AUTOSAR XML (schema 00046)
package /ComponentTypes
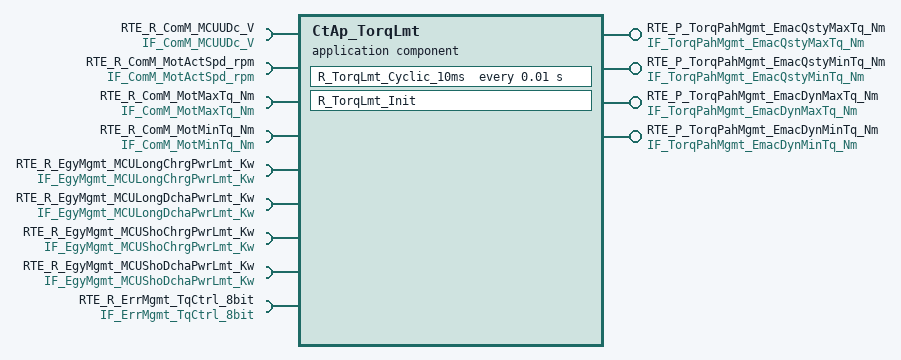
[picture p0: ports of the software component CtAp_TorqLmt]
  application sw component type CtAp_TorqLmt
    4 x provide port:
      RTE_P_TorqPahMgmt_EmacQstyMaxTq_Nm: nonqueued-sender-com-spec{data-element=tec_TorqPahMgmt_EmacQstyMaxTq_Nm, init-value=0}, provided-interface=IF_TorqPahMgmt_EmacQstyMaxTq_Nm
      RTE_P_TorqPahMgmt_EmacQstyMinTq_Nm: nonqueued-sender-com-spec{data-element=tec_TorqPahMgmt_EmacQstyMinTq_Nm, init-value=0}, provided-interface=IF_TorqPahMgmt_EmacQstyMinTq_Nm
      RTE_P_TorqPahMgmt_EmacDynMaxTq_Nm: nonqueued-sender-com-spec{data-element=tec_TorqPahMgmt_EmacDynMaxTq_Nm, init-value=0}, provided-interface=IF_TorqPahMgmt_EmacDynMaxTq_Nm
      RTE_P_TorqPahMgmt_EmacDynMinTq_Nm: nonqueued-sender-com-spec{data-element=tec_TorqPahMgmt_EmacDynMinTq_Nm, init-value=0}, provided-interface=IF_TorqPahMgmt_EmacDynMinTq_Nm
    9 x require port:
      RTE_R_ComM_MCUUDc_V: nonqueued-receiver-com-spec{data-element=tec_ComM_MCUUDc_V, filter=data-filter-type=ALWAYS, init-value=0}, required-interface=IF_ComM_MCUUDc_V
      RTE_R_ComM_MotActSpd_rpm: nonqueued-receiver-com-spec{data-element=tec_ComM_MotActSpd_rpm, filter=data-filter-type=ALWAYS, init-value=0}, required-interface=IF_ComM_MotActSpd_rpm
      RTE_R_ComM_MotMaxTq_Nm: nonqueued-receiver-com-spec{data-element=tec_ComM_MotMaxTq_Nm, filter=data-filter-type=ALWAYS, init-value=0}, required-interface=IF_ComM_MotMaxTq_Nm
      RTE_R_ComM_MotMinTq_Nm: nonqueued-receiver-com-spec{data-element=tec_ComM_MotMinTq_Nm, filter=data-filter-type=ALWAYS, init-value=0}, required-interface=IF_ComM_MotMinTq_Nm
      RTE_R_EgyMgmt_MCULongChrgPwrLmt_Kw: nonqueued-receiver-com-spec{data-element=tec_EgyMgmt_MCULongChrgPwrLmt_Kw, filter=data-filter-type=ALWAYS, init-value=0}, required-interface=IF_EgyMgmt_MCULongChrgPwrLmt_Kw
      RTE_R_EgyMgmt_MCULongDchaPwrLmt_Kw: nonqueued-receiver-com-spec{data-element=tec_EgyMgmt_MCULongDchaPwrLmt_Kw, filter=data-filter-type=ALWAYS, init-value=0}, required-interface=IF_EgyMgmt_MCULongDchaPwrLmt_Kw
      RTE_R_EgyMgmt_MCUShoChrgPwrLmt_Kw: nonqueued-receiver-com-spec{data-element=tec_EgyMgmt_MCUShoChrgPwrLmt_Kw, filter=data-filter-type=ALWAYS, init-value=0}, required-interface=IF_EgyMgmt_MCUShoChrgPwrLmt_Kw
      RTE_R_EgyMgmt_MCUShoDchaPwrLmt_Kw: nonqueued-receiver-com-spec{data-element=tec_EgyMgmt_MCUShoDchaPwrLmt_Kw, filter=data-filter-type=ALWAYS, init-value=0}, required-interface=IF_EgyMgmt_MCUShoDchaPwrLmt_Kw
      RTE_R_ErrMgmt_TqCtrl_8bit: nonqueued-receiver-com-spec{data-element=tec_ErrMgmt_TqCtrl_8bit, filter=data-filter-type=ALWAYS, init-value=0}, required-interface=IF_ErrMgmt_TqCtrl_8bit
    behavior CtAp_TorqLmt_InternalBehavior
      timing event TMT_R_TorqLmt_Cyclic_10ms: start-on-event=R_TorqLmt_Cyclic_10ms, period=0.01
      init event CtAp_TorqLmt_InitEvent: start-on-event=R_TorqLmt_Init
      runnable R_TorqLmt_Cyclic_10ms
        data-receive-point-by-arguments:
          9 x access:
            REC_RTE_R_ComM_MCUUDc_V_tec_ComM_MCUUDc_V: accessed-variable=RTE_R_ComM_MCUUDc_V.tec_ComM_MCUUDc_V
            REC_RTE_R_ComM_MotActSpd_rpm_tec_ComM_MotActSpd_rpm: accessed-variable=RTE_R_ComM_MotActSpd_rpm.tec_ComM_MotActSpd_rpm
            REC_RTE_R_ComM_MotMaxTq_Nm_tec_ComM_MotMaxTq_Nm: accessed-variable=RTE_R_ComM_MotMaxTq_Nm.tec_ComM_MotMaxTq_Nm
            REC_RTE_R_ComM_MotMinTq_Nm_tec_ComM_MotMinTq_Nm: accessed-variable=RTE_R_ComM_MotMinTq_Nm.tec_ComM_MotMinTq_Nm
            REC_RTE_R_EgyMgmt_MCULongChrgPwrLmt_Kw_tec_EgyMgmt_MCULongChrgPwrLmt_Kw: accessed-variable=RTE_R_EgyMgmt_MCULongChrgPwrLmt_Kw.tec_EgyMgmt_MCULongChrgPwrLmt_Kw
            REC_RTE_R_EgyMgmt_MCULongDchaPwrLmt_Kw_tec_EgyMgmt_MCULongDchaPwrLmt_Kw: accessed-variable=RTE_R_EgyMgmt_MCULongDchaPwrLmt_Kw.tec_EgyMgmt_MCULongDchaPwrLmt_Kw
            REC_RTE_R_EgyMgmt_MCUShoChrgPwrLmt_Kw_tec_EgyMgmt_MCUShoChrgPwrLmt_Kw: accessed-variable=RTE_R_EgyMgmt_MCUShoChrgPwrLmt_Kw.tec_EgyMgmt_MCUShoChrgPwrLmt_Kw
            REC_RTE_R_EgyMgmt_MCUShoDchaPwrLmt_Kw_tec_EgyMgmt_MCUShoDchaPwrLmt_Kw: accessed-variable=RTE_R_EgyMgmt_MCUShoDchaPwrLmt_Kw.tec_EgyMgmt_MCUShoDchaPwrLmt_Kw
            REC_RTE_R_ErrMgmt_TqCtrl_8bit_tec_ErrMgmt_TqCtrl_8bit: accessed-variable=RTE_R_ErrMgmt_TqCtrl_8bit.tec_ErrMgmt_TqCtrl_8bit
        data-send-points:
          4 x access:
            SEND_RTE_P_TorqPahMgmt_EmacDynMaxTq_Nm_tec_TorqPahMgmt_EmacDynMaxTq_Nm: accessed-variable=RTE_P_TorqPahMgmt_EmacDynMaxTq_Nm.tec_TorqPahMgmt_EmacDynMaxTq_Nm
            SEND_RTE_P_TorqPahMgmt_EmacDynMinTq_Nm_tec_TorqPahMgmt_EmacDynMinTq_Nm: accessed-variable=RTE_P_TorqPahMgmt_EmacDynMinTq_Nm.tec_TorqPahMgmt_EmacDynMinTq_Nm
            SEND_RTE_P_TorqPahMgmt_EmacQstyMaxTq_Nm_tec_TorqPahMgmt_EmacQstyMaxTq_Nm: accessed-variable=RTE_P_TorqPahMgmt_EmacQstyMaxTq_Nm.tec_TorqPahMgmt_EmacQstyMaxTq_Nm
            SEND_RTE_P_TorqPahMgmt_EmacQstyMinTq_Nm_tec_TorqPahMgmt_EmacQstyMinTq_Nm: accessed-variable=RTE_P_TorqPahMgmt_EmacQstyMinTq_Nm.tec_TorqPahMgmt_EmacQstyMinTq_Nm
      runnable R_TorqLmt_Init
  swc implementation CtAp_TorqLmt_Implementation: behavior=CtAp_TorqLmt_InternalBehavior
    code-descriptors:
      code Default: artifact-descriptors=autosar-engineering-object=category=SWOBJ
